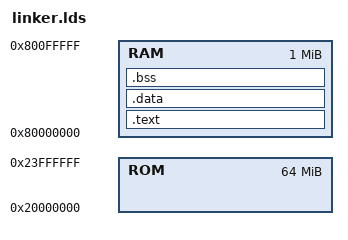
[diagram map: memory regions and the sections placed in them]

ENTRY(_start)

MEMORY
{
        ROM : ORIGIN = 0x20000000, LENGTH = 64M
        RAM : ORIGIN = 0x80000000, LENGTH = 1M
}

SECTIONS
{
        /**********************************************************************
         *                                                                    *
         **********************************************************************/
        .text :
        {
                _stext = .;
                *(.text)
                *(.text.*)
                *(.vectors)
                *(.rodata)
                *(.rodata.*)
                *(.srodata)
                *(.srodata.*)
                *(.riscv.attributes)
                . = ALIGN(0x4);
                PROVIDE(_debug_flag = .);
                BYTE(0x00);
                . = ALIGN(0x10);
                _etext = .;
        } > RAM
        /**********************************************************************
         *                                                                    *
         **********************************************************************/
        .data :
        {
                _sdata = .;
                *(.data)
                *(.data.*)
                *(.sdata)
                *(.sdata.*)
                *(.sdata2)
                *(.sdata2.*)
                . = ALIGN(0x10);
                _edata = .;
        } > RAM
        /**********************************************************************
         *                                                                    *
         **********************************************************************/
        .bss ADDR(.data) + SIZEOF(.data) (NOLOAD) :
        {
                _sbss = .;
                *(.bss)
                *(.bss.*)
                *(.sbss)
                *(.sbss.*)
                *(COMMON)
                _ebss = .;
        } > RAM
        /**********************************************************************
         *                                                                    *
         **********************************************************************/
        .debug_info     0 : { *(.debug_info) }
        .debug_abbrev   0 : { *(.debug_abbrev) }
        .debug_aranges  0 : { obj/startup.o(.debug_aranges) *(.debug_aranges) }
        .debug_frame    0 : { *(.debug_frame) }
        .debug_line     0 : { *(.debug_line) }
        .debug_line_str 0 : { *(.debug_line_str) }
        .debug_loclists 0 : { *(.debug_loclists) }
        .debug_macro    0 : { *(.debug_macro) }
        .debug_names    0 : { *(.debug_names) }
        .debug_rnglists 0 : { *(.debug_rnglists) }
        .debug_str      0 : { *(.debug_str) }
        /**********************************************************************
         *                                                                    *
         **********************************************************************/
        /DISCARD/ :
        {
                *(*)
        }
}

